# MK21FA12 register map
Vendor: Freescale Semiconductor, Inc.; Series: Kinetis_K; File version: 1.6
CPU: CM4 r0p1, little endian, no MPU, FPU, VTOR, 4 interrupt priority bits
Registers are 32-bit, read-write, reset 0x0 unless marked. A register's access mark holds for its fields unless they carry their own. Offsets are from the block's base; [hi:lo] are bit positions; 'fields as' and 'values as' point back to an identical list.

## CRC — Cyclic Redundancy Check
Base 0x40032000; register names take the prefix CRC_
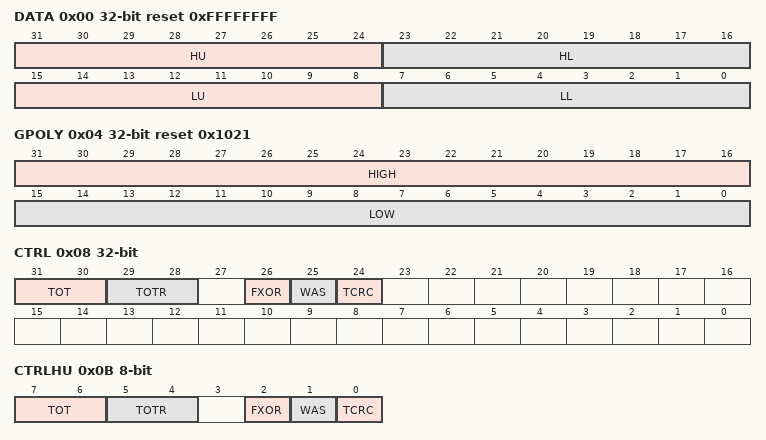
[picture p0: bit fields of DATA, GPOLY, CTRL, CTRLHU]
0x00 DATA reset 0xFFFFFFFF (CRC view) — CRC Data register
  [31:24] HU — CRC High Upper Byte
  [23:16] HL — CRC High Lower Byte
  [15:8] LU — CRC Low Upper Byte
  [7:0] LL — CRC Low Lower Byte
0x00 DATAL 16-bit reset 0xFFFF (CRC view) — CRC_DATAL register.
  [15:0] DATAL — DATAL stores the lower 16 bits of the 16/32 bit CRC
0x00 DATALL 8-bit reset 0xFF (CRC view) — CRC_DATALL register.
  [7:0] DATALL — CRCLL stores the first 8 bits of the 32 bit DATA
0x01 DATALU 8-bit reset 0xFF — CRC_DATALU register.
  [7:0] DATALU — DATALL stores the second 8 bits of the 32 bit CRC
0x02 DATAH 16-bit reset 0xFFFF (CRC view) — CRC_DATAH register.
  [15:0] DATAH — DATAH stores the high 16 bits of the 16/32 bit CRC
0x02 DATAHL 8-bit reset 0xFF (CRC view) — CRC_DATAHL register.
  [7:0] DATAHL — DATAHL stores the third 8 bits of the 32 bit CRC
0x03 DATAHU 8-bit reset 0xFF — CRC_DATAHU register.
  [7:0] DATAHU — DATAHU stores the fourth 8 bits of the 32 bit CRC
0x04 GPOLY reset 0x1021 (CRC view) — CRC Polynomial register
  [31:16] HIGH — High Polynominal Half-word
  [15:0] LOW — Low Polynominal Half-word
0x04 GPOLYL 16-bit reset 0xFFFF (CRC view) — CRC_GPOLYL register.
  [15:0] GPOLYL — POLYL stores the lower 16 bits of the 16/32 bit CRC polynomial value
0x04 GPOLYLL 8-bit reset 0xFF (CRC view) — CRC_GPOLYLL register.
  [7:0] GPOLYLL — POLYLL stores the first 8 bits of the 32 bit CRC
0x05 GPOLYLU 8-bit reset 0xFF — CRC_GPOLYLU register.
  [7:0] GPOLYLU — POLYLL stores the second 8 bits of the 32 bit CRC
0x06 GPOLYH 16-bit reset 0xFFFF (CRC view) — CRC_GPOLYH register.
  [15:0] GPOLYH — POLYH stores the high 16 bits of the 16/32 bit CRC polynomial value
0x06 GPOLYHL 8-bit reset 0xFF (CRC view) — CRC_GPOLYHL register.
  [7:0] GPOLYHL — POLYHL stores the third 8 bits of the 32 bit CRC
0x07 GPOLYHU 8-bit reset 0xFF — CRC_GPOLYHU register.
  [7:0] GPOLYHU — POLYHU stores the fourth 8 bits of the 32 bit CRC
0x08 CTRL — CRC Control register
  [31:30] TOT — Type Of Transpose For Writes
    0=No transposition; 1=Bits in bytes are transposed; bytes are not transposed; 2=Both bits in bytes and bytes are transposed; 3=Only bytes are transposed; no bits in a byte are transposed
  [29:28] TOTR — Type Of Transpose For Read
    values as TOT
  [26] FXOR — Complement Read Of CRC Data Register
    0=No XOR on reading; 1=Invert or complement the read value of the CRC Data register
  [25] WAS — Write CRC Data Register As Seed
    0=Writes to the CRC data register are data values; 1=Writes to the CRC data register are seed values
  [24] TCRC — Width of CRC protocol.
    0=16-bit CRC protocol; 1=32-bit CRC protocol
0x0B CTRLHU 8-bit — CRC_CTRLHU register.
  [7:6] TOT
    0=No Transposition; 1=Bits in bytes are transposed, bytes are not transposed; 2=Both bits in bytes and bytes are transposed; 3=Only bytes are transposed; no bits in a byte are transposed
  [5:4] TOTR
    values as TOT
  [2] FXOR
    0=No XOR on reading; 1=Invert or complement the read value of CRC data register
  [1] WAS
    0=Writes to CRC data register are data values; 1=Writes to CRC data reguster are seed values
  [0] TCRC
    0=16-bit CRC protocol; 1=32-bit CRC protocol

## USBDCD — USB Device Charger Detection module
Base 0x40035000; register names take the prefix USBDCD_
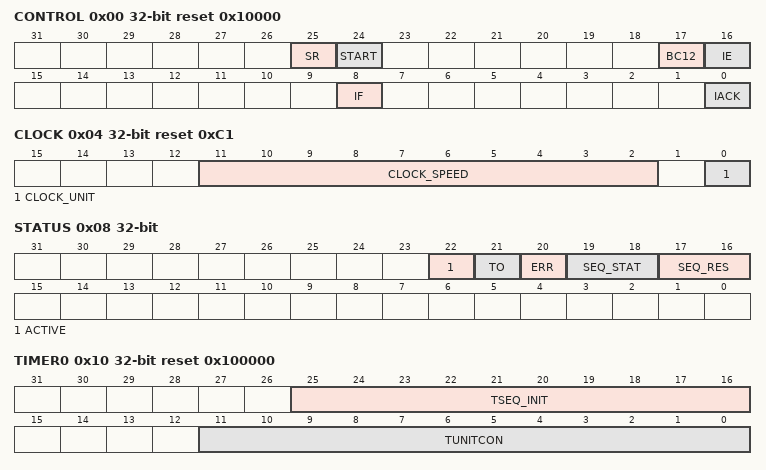
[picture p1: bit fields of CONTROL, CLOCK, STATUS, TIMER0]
0x00 CONTROL reset 0x10000
  [25] SR wo — Software Reset
    0=Do not perform a software reset; 1=Perform a software reset
  [24] START wo — Start Change Detection Sequence
    0=Do not start the sequence. Writes of this value have no effect.; 1=Initiate the charger detection sequence. If the sequence is already running, writes of this value have no effect.
  [17] BC12 — BC1.2 compatibility. This bit cannot be changed after start detection.
    0=Compatible with BC1.1 (default); 1=Compatible with BC1.2
  [16] IE — Interrupt Enable
    0=Disable interrupts to the system; 1=Enable interrupts to the system
  [8] IF ro — Interrupt Flag
    0=No interrupt is pending; 1=An interrupt is pending
  [0] IACK wo — Interrupt Acknowledge
    0=Do not clear the interrupt; 1=Clear the IF bit (interrupt flag)
0x04 CLOCK reset 0xC1
  [11:2] CLOCK_SPEED — Numerical Value of Clock Speed in Binary
  [0] CLOCK_UNIT — Unit of Measurement Encoding for Clock Speed
    0=kHz Speed (between 1 kHz and 1023 kHz); 1=MHz Speed (between 1 MHz and 1023 MHz)
0x08 STATUS ro
  [22] ACTIVE — Active Status Indicator
    0=The sequence is not running; 1=The sequence is running
  [21] TO — Timeout Flag
    0=The detection sequence has not been running for over 1 s; 1=It has been over 1 s since the data pin contact was detected and debounced
  [20] ERR — Error Flag
    0=No sequence errors; 1=Error in the detection sequence. See the SEQ_STAT field to determine the phase in which the error occurred.
  [19:18] SEQ_STAT — Charger Detection Sequence Status
    0=The module is either not enabled, or the module is enabled but the data pins have not yet been detected; 1=Data pin contact detection is complete; 2=Charging port detection is complete; 3=Charger type detection is complete
  [17:16] SEQ_RES — Charger Detection Sequence Results
    0=No results to report; 1=Attached to a standard host. Must comply with USB 2.0 by drawing only 2.5 mA (max) until connected.; 2=Attached to a charging port. The exact meaning depends on bit 18: 0: Attached to either a charging host or a dedicated charger. The charger type detection has not completed. 1: Attached to a charging host. The charger type detection has completed.; 3=Attached to a dedicated charger
0x10 TIMER0 reset 0x100000
  [25:16] TSEQ_INIT — Sequence Initiation Time
  [11:0] TUNITCON ro — Unit Connection Timer Elapse (in ms)
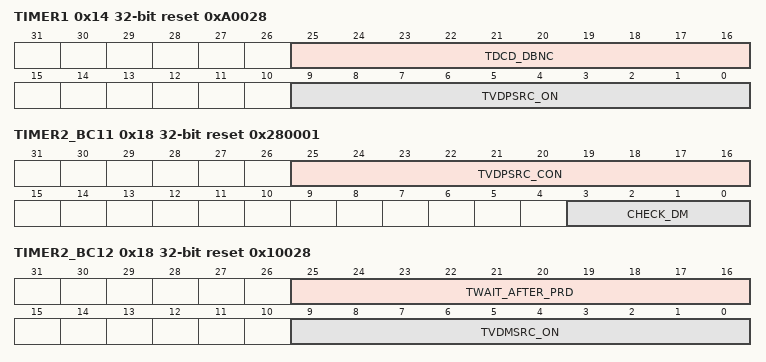
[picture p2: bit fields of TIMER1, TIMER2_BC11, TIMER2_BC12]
0x14 TIMER1 reset 0xA0028
  [25:16] TDCD_DBNC — Time Period to Debounce D+ Signal
  [9:0] TVDPSRC_ON — Time Period Comparator Enabled
0x18 TIMER2_BC11 reset 0x280001 (USBDCD view)
  [25:16] TVDPSRC_CON — Time Period Before Enabling D+ Pullup
  [3:0] CHECK_DM — Time Before Check of D- Line
0x18 TIMER2_BC12 reset 0x10028 (USBDCD view)
  [25:16] TWAIT_AFTER_PRD — Sets the amount of time (in ms) that the module waits after primary detection before start to secondary detection
  [9:0] TVDMSRC_ON — Sets the amount of time (in ms) that the module enables the VDM_SRC. Valid values are 0-40ms.

## Notices in the file
Redistribution and use in source and binary forms, with or without modification,
are permitted provided that the following conditions are met:
o Redistributions of source code must retain the above copyright notice, this list
of conditions and the following disclaimer.
o Redistributions in binary form must reproduce the above copyright notice, this
list of conditions and the following disclaimer in the documentation and/or
other materials provided with the distribution.
o Neither the name of Freescale Semiconductor, Inc. nor the names of its
contributors may be used to endorse or promote products derived from this
software without specific prior written permission.
THIS SOFTWARE IS PROVIDED BY THE COPYRIGHT HOLDERS AND CONTRIBUTORS "AS IS" AND
ANY EXPRESS OR IMPLIED WARRANTIES, INCLUDING, BUT NOT LIMITED TO, THE IMPLIED
WARRANTIES OF MERCHANTABILITY AND FITNESS FOR A PARTICULAR PURPOSE ARE
DISCLAIMED. IN NO EVENT SHALL THE COPYRIGHT HOLDER OR CONTRIBUTORS BE LIABLE FOR
ANY DIRECT, INDIRECT, INCIDENTAL, SPECIAL, EXEMPLARY, OR CONSEQUENTIAL DAMAGES
(INCLUDING, BUT NOT LIMITED TO, PROCUREMENT OF SUBSTITUTE GOODS OR SERVICES;
LOSS OF USE, DATA, OR PROFITS; OR BUSINESS INTERRUPTION) HOWEVER CAUSED AND ON
ANY THEORY OF LIABILITY, WHETHER IN CONTRACT, STRICT LIABILITY, OR TORT
(INCLUDING NEGLIGENCE OR OTHERWISE) ARISING IN ANY WAY OUT OF THE USE OF THIS
SOFTWARE, EVEN IF ADVISED OF THE POSSIBILITY OF SUCH DAMAGE.
